AUTOSAR XML (schema 00046)
package /ComponentTypes
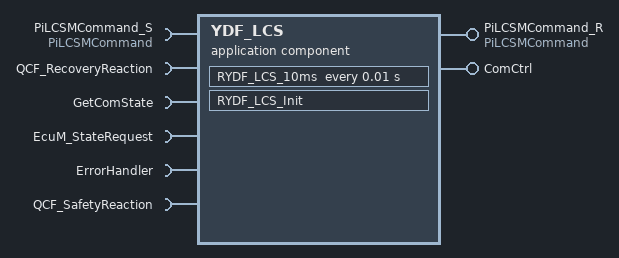
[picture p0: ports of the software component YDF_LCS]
  application sw component type YDF_LCS
    provide port PiLCSMCommand_R: nonqueued-sender-com-spec{data-element=DeCommand, init-value=0}, provided-interface=PiLCSMCommand
    require port PiLCSMCommand_S: nonqueued-receiver-com-spec{data-element=DeCommand, filter=data-filter-type=ALWAYS, init-value=0}, required-interface=PiLCSMCommand
    require port QCF_RecoveryReaction: nonqueued-receiver-com-spec{data-element=State, filter=data-filter-type=ALWAYS, init-value=constant-reference=QCF_RECOVERY_REAC_DEFAULT}, required-interface=QCF_RecoveryReaction
    provide port ComCtrl: nonqueued-sender-com-spec{data-element=ComState, init-value=constant-reference=COM_STATE_DEFAULT}, provided-interface=ComCtrl
    4 x require port:
      GetComState: nonqueued-receiver-com-spec{data-element=State, filter=data-filter-type=ALWAYS, init-value=constant-reference=COM_STATE_DEFAULT}, required-interface=GetComState
      EcuM_StateRequest: required-com-specs=[GetStateWrapper, RequestRUN, RequestPOSTRUN, ReleaseRUN, ReleasePOSTRUN], required-interface=EcuM_StateRequest
      ErrorHandler: client-com-spec=ReportError, required-interface=ErrorHandler
      QCF_SafetyReaction: nonqueued-receiver-com-spec{data-element=State, filter=data-filter-type=ALWAYS, init-value=constant-reference=QCF_SAFETY_REAC_DEFAULT}, required-interface=QCF_SafetyReaction
    behavior YDF_LCS_InternalBehavior
      timing event TMT_RYDF_LCS_10ms: start-on-event=RYDF_LCS_10ms, period=0.01
      init event RYDF_LCS_InitEvent: start-on-event=RYDF_LCS_Init
      runnable RYDF_LCS_10ms
        data-receive-point-by-arguments:
          4 x access:
            REC_PiLCSMCommand_S_DeCommand: accessed-variable=PiLCSMCommand_S.DeCommand
            REC_QCF_RecoveryReaction_State: accessed-variable=QCF_RecoveryReaction.State
            REC_GetComState_State: accessed-variable=GetComState.State
            REC_QCF_SafetyReaction_State: accessed-variable=QCF_SafetyReaction.State
        data-send-points:
          access SEND_PiLCSMCommand_R_DeCommand: accessed-variable=PiLCSMCommand_R.DeCommand
          access SEND_ComCtrl_ComState: accessed-variable=ComCtrl.ComState
        4 x sync call:
          SC_EcuM_StateRequest_ReleasePOSTRUN: operation=EcuM_StateRequest.ReleasePOSTRUN
          SC_EcuM_StateRequest_ReleaseRUN: operation=EcuM_StateRequest.ReleaseRUN
          SC_EcuM_StateRequest_RequestPOSTRUN: operation=EcuM_StateRequest.RequestPOSTRUN
          SC_EcuM_StateRequest_RequestRUN: operation=EcuM_StateRequest.RequestRUN
        async call SC_ErrorHandler_ReportError: operation=ErrorHandler.ReportError
      runnable RYDF_LCS_Init
  swc implementation YDF_LCS_Implementation: behavior=YDF_LCS_InternalBehavior
    code-descriptors:
      code Default: artifact-descriptors=autosar-engineering-object=category=SWSRC
